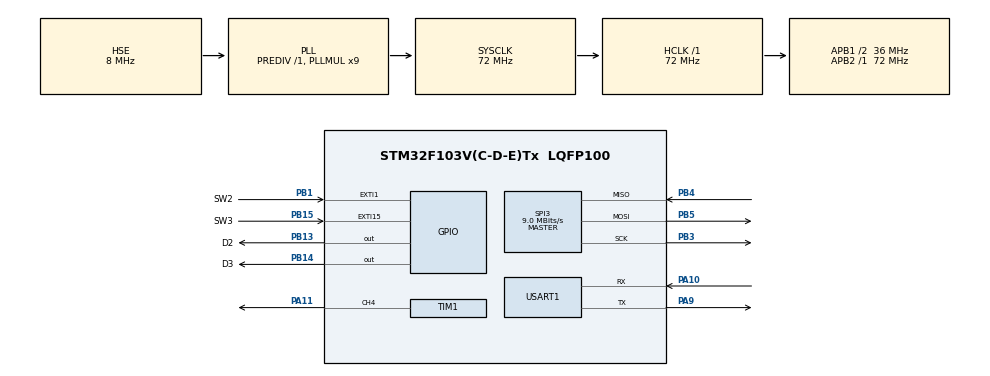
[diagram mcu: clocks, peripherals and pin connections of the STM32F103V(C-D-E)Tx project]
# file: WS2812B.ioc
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Dma.Request0=TIM1_CH4/TRIG/COM
Dma.TIM1_CH4/TRIG/COM.0.Direction=DMA_MEMORY_TO_PERIPH
Dma.TIM1_CH4/TRIG/COM.0.Instance=DMA1_Channel4
Dma.TIM1_CH4/TRIG/COM.0.MemDataAlignment=DMA_MDATAALIGN_HALFWORD
Dma.TIM1_CH4/TRIG/COM.0.MemInc=DMA_MINC_ENABLE
Dma.TIM1_CH4/TRIG/COM.0.Mode=DMA_NORMAL
Dma.TIM1_CH4/TRIG/COM.0.PeriphDataAlignment=DMA_PDATAALIGN_HALFWORD
Dma.TIM1_CH4/TRIG/COM.0.PeriphInc=DMA_PINC_DISABLE
Dma.TIM1_CH4/TRIG/COM.0.Priority=DMA_PRIORITY_MEDIUM
Mcu.Family=STM32F1
Mcu.Name=STM32F103V(C-D-E)Tx
Mcu.Package=LQFP100
NVIC.DMA1_Channel4_IRQn=true\:0\:0\:false\:false\:true\:false\:true
NVIC.EXTI15_10_IRQn=true\:0\:0\:false\:false\:true\:true\:true
NVIC.EXTI1_IRQn=true\:0\:0\:false\:false\:true\:true\:true
NVIC.PriorityGroup=NVIC_PRIORITYGROUP_4
NVIC.USART1_IRQn=true\:0\:0\:false\:false\:true\:true\:true
OSC_IN.Mode=HSE-External-Oscillator
OSC_IN.Signal=RCC_OSC_IN
OSC_OUT.Mode=HSE-External-Oscillator
OSC_OUT.Signal=RCC_OSC_OUT
PA10.Mode=Asynchronous
PA10.Signal=USART1_RX
PA11.Signal=S_TIM1_CH4
PA13.Mode=Serial_Wire
PA13.Signal=SYS_JTMS-SWDIO
PA14.Mode=Serial_Wire
PA14.Signal=SYS_JTCK-SWCLK
PA9.Mode=Asynchronous
PA9.Signal=USART1_TX
PB1.GPIO_Label=SW2
PB1.GPIO_ModeDefaultEXTI=GPIO_MODE_IT_RISING
PB1.Signal=GPXTI1
PB13.GPIO_Label=D2
PB13.GPIO_ModeDefaultOutputPP=GPIO_MODE_OUTPUT_PP
PB13.GPIO_PuPd=GPIO_NOPULL
PB13.GPIO_Speed=GPIO_SPEED_FREQ_LOW
PB13.PinState=GPIO_PIN_RESET
PB13.Signal=GPIO_Output
PB14.GPIO_Label=D3
PB14.GPIO_ModeDefaultOutputPP=GPIO_MODE_OUTPUT_PP
PB14.GPIO_PuPd=GPIO_NOPULL
PB14.GPIO_Speed=GPIO_SPEED_FREQ_LOW
PB14.PinState=GPIO_PIN_RESET
PB14.Signal=GPIO_Output
PB15.GPIO_Label=SW3
PB15.GPIO_ModeDefaultEXTI=GPIO_MODE_IT_RISING
PB15.Signal=GPXTI15
PB3.Mode=Full_Duplex_Master
PB3.Signal=SPI3_SCK
PB4.Mode=Full_Duplex_Master
PB4.Signal=SPI3_MISO
PB5.Mode=Full_Duplex_Master
PB5.Signal=SPI3_MOSI
ProjectManager.HeapSize=0x200
ProjectManager.StackSize=0x400
ProjectManager.TargetToolchain=MDK-ARM V5.27
RCC.AHBFreq_Value=72000000
RCC.APB1CLKDivider=RCC_HCLK_DIV2
RCC.APB1Freq_Value=36000000
RCC.APB1TimFreq_Value=72000000
RCC.APB2Freq_Value=72000000
RCC.APB2TimFreq_Value=72000000
RCC.HCLKFreq_Value=72000000
RCC.PLLMUL=RCC_PLL_MUL9
RCC.PLLSourceVirtual=RCC_PLLSOURCE_HSE
RCC.SYSCLKFreq_VALUE=72000000
RCC.SYSCLKSource=RCC_SYSCLKSOURCE_PLLCLK
RCC.USBFreq_Value=72000000
SH.S_TIM1_CH4.0=TIM1_CH4,PWM Generation4 CH4
SPI3.BaudRatePrescaler=SPI_BAUDRATEPRESCALER_4
SPI3.CalculateBaudRate=9.0 MBits/s
SPI3.DataSize=SPI_DATASIZE_16BIT
SPI3.Direction=SPI_DIRECTION_2LINES
SPI3.Mode=SPI_MODE_MASTER
SPI3.VirtualType=VM_MASTER
TIM1.AutoReloadPreload=TIM_AUTORELOAD_PRELOAD_ENABLE
TIM1.Channel-PWM\ Generation4\ CH4=TIM_CHANNEL_4
TIM1.Period=80-1
USART1.VirtualMode=VM_ASYNC
board=custom

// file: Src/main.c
/* USER CODE BEGIN Header */
/**
  ******************************************************************************
  * @file           : main.c
  * @brief          : Main program body
  ******************************************************************************
  * @attention
  *
  * <h2><center>&copy; Copyright (c) 2020 STMicroelectronics.
  * All rights reserved.</center></h2>
  *
  * This software component is licensed by ST under BSD 3-Clause license,
  * the "License"; You may not use this file except in compliance with the
  * License. You may obtain a copy of the License at:
  *                        opensource.org/licenses/BSD-3-Clause
  *
  ******************************************************************************
  */
/* USER CODE END Header */

#include "main.h"
#include "dma.h"
#include "spi.h"
#include "tim.h"
#include "usart.h"
#include "gpio.h"

/* USER CODE BEGIN Includes */
#include "user.h"

/* USER CODE END Includes */

void SystemClock_Config(void);

int main(void)
{

  /* MCU Configuration--------------------------------------------------------*/

  /* Reset of all peripherals, Initializes the Flash interface and the Systick. */
  HAL_Init();

  /* Configure the system clock */
  SystemClock_Config();

  /* Initialize all configured peripherals */
  MX_GPIO_Init();
  MX_DMA_Init();
  MX_TIM1_Init();
  MX_USART1_UART_Init();
  MX_SPI3_Init();
  /* USER CODE BEGIN 2 */

  user_init();

  /* USER CODE END 2 */

  /* Infinite loop */
  while (1)
  {

    /* USER CODE BEGIN 3 */

      user_main();

      HAL_GPIO_TogglePin(D2_GPIO_Port,D2_Pin);

  }
  /* USER CODE END 3 */
}

void SystemClock_Config(void)
{
  RCC_OscInitTypeDef RCC_OscInitStruct = {0};
  RCC_ClkInitTypeDef RCC_ClkInitStruct = {0};

  /** Initializes the CPU, AHB and APB busses clocks
  */
  RCC_OscInitStruct.OscillatorType = RCC_OSCILLATORTYPE_HSE;
  RCC_OscInitStruct.HSEState = RCC_HSE_ON;
  RCC_OscInitStruct.HSEPredivValue = RCC_HSE_PREDIV_DIV1;
  RCC_OscInitStruct.HSIState = RCC_HSI_ON;
  RCC_OscInitStruct.PLL.PLLState = RCC_PLL_ON;
  RCC_OscInitStruct.PLL.PLLSource = RCC_PLLSOURCE_HSE;
  RCC_OscInitStruct.PLL.PLLMUL = RCC_PLL_MUL9;
  if (HAL_RCC_OscConfig(&RCC_OscInitStruct) != HAL_OK)
  {
    Error_Handler();
  }
  /** Initializes the CPU, AHB and APB busses clocks
  */
  RCC_ClkInitStruct.ClockType = RCC_CLOCKTYPE_HCLK|RCC_CLOCKTYPE_SYSCLK
                              |RCC_CLOCKTYPE_PCLK1|RCC_CLOCKTYPE_PCLK2;
  RCC_ClkInitStruct.SYSCLKSource = RCC_SYSCLKSOURCE_PLLCLK;
  RCC_ClkInitStruct.AHBCLKDivider = RCC_SYSCLK_DIV1;
  RCC_ClkInitStruct.APB1CLKDivider = RCC_HCLK_DIV2;
  RCC_ClkInitStruct.APB2CLKDivider = RCC_HCLK_DIV1;

  if (HAL_RCC_ClockConfig(&RCC_ClkInitStruct, FLASH_LATENCY_2) != HAL_OK)
  {
    Error_Handler();
  }
}

void Error_Handler(void)
{
}

/************************ (C) COPYRIGHT STMicroelectronics *****END OF FILE****/
